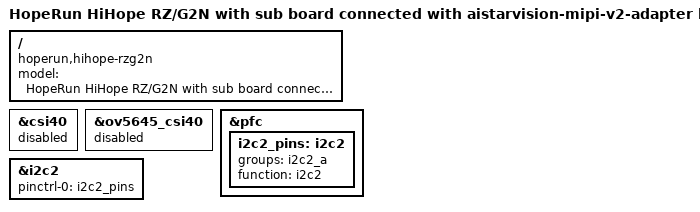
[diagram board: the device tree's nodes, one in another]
// SPDX-License-Identifier: GPL-2.0
/*
 * Device Tree Source for the HiHope RZ/G2N Rev.2.0 board
 * connected with aistarvision-mipi-v2-adapter board
 *
 * Copyright (C) 2021 Renesas Electronics Corp.
 */

/dts-v1/;
#include "r8a774b1-hihope-rzg2n-rev2-ex.dts"
#include "hihope-rzg2-ex-aistarvision-mipi-adapter-2.4.dtsi"

/ {
	model = "HopeRun HiHope RZ/G2N with sub board connected with aistarvision-mipi-v2-adapter board";
	compatible = "hoperun,hihope-rzg2n", "renesas,r8a774b1";
};

/*
 * HiHope RZ/G2N Rev.2.0 board has a hardware limitation about pull-up resistors
 * on I2C lines.
 * So just support only CSI20.
 */
&csi40 {
	status = "disabled";
};

&ov5645_csi40 {
	status = "disabled";
};

&pfc {
	i2c2_pins: i2c2 {
		groups = "i2c2_a";
		function = "i2c2";
	};
};

&i2c2 {
	pinctrl-0 = <&i2c2_pins>;
	pinctrl-names = "default";

	status = "okay";
};
